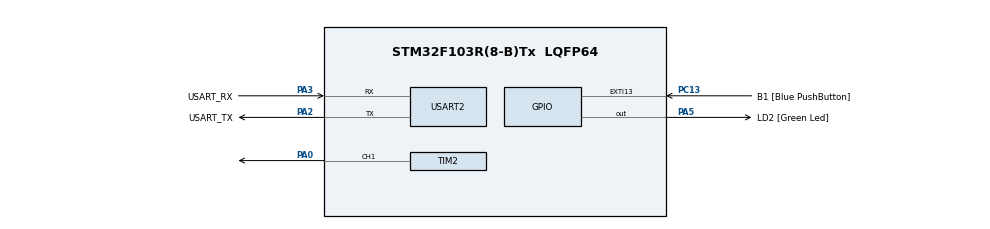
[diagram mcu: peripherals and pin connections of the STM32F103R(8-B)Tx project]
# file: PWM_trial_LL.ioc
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Mcu.Family=STM32F1
Mcu.Name=STM32F103R(8-B)Tx
Mcu.Package=LQFP64
NVIC.EXTI15_10_IRQn=true\:0\:0\:false\:false\:true\:true\:true
NVIC.PriorityGroup=NVIC_PRIORITYGROUP_4
PA0-WKUP.Signal=S_TIM2_CH1_ETR
PA13.GPIO_Label=TMS
PA13.Mode=Serial_Wire
PA13.Signal=SYS_JTMS-SWDIO
PA14.GPIO_Label=TCK
PA14.Mode=Serial_Wire
PA14.Signal=SYS_JTCK-SWCLK
PA2.GPIO_Label=USART_TX
PA2.GPIO_Mode=GPIO_MODE_AF_PP
PA2.GPIO_PuPd=GPIO_NOPULL
PA2.GPIO_Speed=GPIO_SPEED_FREQ_LOW
PA2.Mode=Asynchronous
PA2.Signal=USART2_TX
PA3.GPIO_Label=USART_RX
PA3.GPIO_Mode=GPIO_MODE_AF_PP
PA3.GPIO_PuPd=GPIO_NOPULL
PA3.GPIO_Speed=GPIO_SPEED_FREQ_LOW
PA3.Mode=Asynchronous
PA3.Signal=USART2_RX
PA5.GPIO_Label=LD2 [Green Led]
PA5.GPIO_ModeDefaultOutputPP=GPIO_MODE_OUTPUT_PP
PA5.GPIO_PuPd=GPIO_NOPULL
PA5.GPIO_Speed=GPIO_SPEED_FREQ_LOW
PA5.Signal=GPIO_Output
PB3.GPIO_Label=SWO
PB3.Signal=SYS_JTDO-TRACESWO
PC13-TAMPER-RTC.GPIO_Label=B1 [Blue PushButton]
PC13-TAMPER-RTC.GPIO_PuPd=GPIO_NOPULL
PC13-TAMPER-RTC.Signal=GPXTI13
PC14-OSC32_IN.Mode=LSE-External-Oscillator
PC14-OSC32_IN.Signal=RCC_OSC32_IN
PC15-OSC32_OUT.Mode=LSE-External-Oscillator
PC15-OSC32_OUT.Signal=RCC_OSC32_OUT
PD0-OSC_IN.Mode=HSE-External-Clock-Source
PD0-OSC_IN.Signal=RCC_OSC_IN
PD1-OSC_OUT.Mode=HSE-External-Clock-Source
PD1-OSC_OUT.Signal=RCC_OSC_OUT
ProjectManager.HeapSize=0x200
ProjectManager.StackSize=0x400
ProjectManager.TargetToolchain=SW4STM32
RCC.AHBFreq_Value=64000000
RCC.APB1CLKDivider=RCC_HCLK_DIV2
RCC.APB1Freq_Value=32000000
RCC.APB1TimFreq_Value=64000000
RCC.APB2Freq_Value=64000000
RCC.APB2TimFreq_Value=64000000
RCC.HCLKFreq_Value=64000000
RCC.PLLMUL=RCC_PLL_MUL16
RCC.RTCClockSelection=RCC_RTCCLKSOURCE_LSE
RCC.SYSCLKFreq_VALUE=64000000
RCC.SYSCLKSource=RCC_SYSCLKSOURCE_PLLCLK
RCC.USBFreq_Value=64000000
SH.S_TIM2_CH1_ETR.0=TIM2_CH1,PWM Generation1 CH1
TIM2.Channel-PWM\ Generation1\ CH1=TIM_CHANNEL_1
TIM2.Period=1000
TIM2.Prescaler=20
USART2.VirtualMode=VM_ASYNC
VP_TIM2_VS_ClockSourceINT.Mode=Internal
board=NUCLEO-F103RB

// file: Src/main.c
/* USER CODE BEGIN Header */
/**
  ******************************************************************************
  * @file           : main.c
  * @brief          : Main program body
  ******************************************************************************
  * @attention
  *
  * <h2><center>&copy; Copyright (c) 2020 STMicroelectronics.
  * All rights reserved.</center></h2>
  *
  * This software component is licensed by ST under BSD 3-Clause license,
  * the "License"; You may not use this file except in compliance with the
  * License. You may obtain a copy of the License at:
  *                        opensource.org/licenses/BSD-3-Clause
  *
  ******************************************************************************
  */
/* USER CODE END Header */

#include "main.h"

/* USER CODE BEGIN Includes */

#include "PWM_LL_library.h"

/* USER CODE END Includes */

void SystemClock_Config(void);
static void MX_GPIO_Init(void);
static void MX_TIM2_Init(void);
static void MX_USART2_UART_Init(void);

int main(void)
{

  /* MCU Configuration--------------------------------------------------------*/

  /* Reset of all peripherals, Initializes the Flash interface and the Systick. */

  LL_APB2_GRP1_EnableClock(LL_APB2_GRP1_PERIPH_AFIO);
  LL_APB1_GRP1_EnableClock(LL_APB1_GRP1_PERIPH_PWR);

  NVIC_SetPriorityGrouping(NVIC_PRIORITYGROUP_4);

  /* System interrupt init*/

  /** NOJTAG: JTAG-DP Disabled and SW-DP Enabled
  */
  LL_GPIO_AF_Remap_SWJ_NOJTAG();

  /* Configure the system clock */
  SystemClock_Config();

  /* Initialize all configured peripherals */
  MX_GPIO_Init();
  MX_TIM2_Init();
  MX_USART2_UART_Init();
  /* USER CODE BEGIN 2 */

  TIM_handler_t tim;
  PWM_init(&tim, TIM2, 64000); 					// frequency 64000 Hz
  PWM_setDutyCycle(&tim, 10);					//duty cycle 10%
  PWM_enable(&tim);								//enabling PWM
  for(int i = 0; i < 16000000; i++) __NOP();	// delay
  PWM_disable(&tim);							//disabling PWM
  PWM_setDutyCycle(&tim, 90);					//setting duty cycle to 90%
  PWM_enable(&tim);								//enabling

  /* USER CODE END 2 */

  /* Infinite loop */
  while (1)
  {

  }
}

void SystemClock_Config(void)
{
  LL_FLASH_SetLatency(LL_FLASH_LATENCY_2);

   if(LL_FLASH_GetLatency() != LL_FLASH_LATENCY_2)
  {
    Error_Handler();
  }
  LL_RCC_HSI_SetCalibTrimming(16);
  LL_RCC_HSI_Enable();

   /* Wait till HSI is ready */
  while(LL_RCC_HSI_IsReady() != 1)
  {

  }
  LL_RCC_PLL_ConfigDomain_SYS(LL_RCC_PLLSOURCE_HSI_DIV_2, LL_RCC_PLL_MUL_16);
  LL_RCC_PLL_Enable();

   /* Wait till PLL is ready */
  while(LL_RCC_PLL_IsReady() != 1)
  {

  }
  LL_RCC_SetAHBPrescaler(LL_RCC_SYSCLK_DIV_1);
  LL_RCC_SetAPB1Prescaler(LL_RCC_APB1_DIV_2);
  LL_RCC_SetAPB2Prescaler(LL_RCC_APB2_DIV_1);
  LL_RCC_SetSysClkSource(LL_RCC_SYS_CLKSOURCE_PLL);

   /* Wait till System clock is ready */
  while(LL_RCC_GetSysClkSource() != LL_RCC_SYS_CLKSOURCE_STATUS_PLL)
  {

  }
  LL_Init1msTick(64000000);
  LL_SYSTICK_SetClkSource(LL_SYSTICK_CLKSOURCE_HCLK);
  LL_SetSystemCoreClock(64000000);
}

static void MX_TIM2_Init(void)
{

  LL_TIM_InitTypeDef TIM_InitStruct = {0};
  LL_TIM_OC_InitTypeDef TIM_OC_InitStruct = {0};

  LL_GPIO_InitTypeDef GPIO_InitStruct = {0};

  /* Peripheral clock enable */
  LL_APB1_GRP1_EnableClock(LL_APB1_GRP1_PERIPH_TIM2);

  TIM_InitStruct.Prescaler = 20;
  TIM_InitStruct.CounterMode = LL_TIM_COUNTERMODE_UP;
  TIM_InitStruct.Autoreload = 1000;
  TIM_InitStruct.ClockDivision = LL_TIM_CLOCKDIVISION_DIV1;
  LL_TIM_Init(TIM2, &TIM_InitStruct);
  LL_TIM_DisableARRPreload(TIM2);
  LL_TIM_SetClockSource(TIM2, LL_TIM_CLOCKSOURCE_INTERNAL);
  LL_TIM_OC_EnablePreload(TIM2, LL_TIM_CHANNEL_CH1);
  TIM_OC_InitStruct.OCMode = LL_TIM_OCMODE_PWM1;
  TIM_OC_InitStruct.OCState = LL_TIM_OCSTATE_DISABLE;
  TIM_OC_InitStruct.OCNState = LL_TIM_OCSTATE_DISABLE;
  TIM_OC_InitStruct.CompareValue = 0;
  TIM_OC_InitStruct.OCPolarity = LL_TIM_OCPOLARITY_HIGH;
  LL_TIM_OC_Init(TIM2, LL_TIM_CHANNEL_CH1, &TIM_OC_InitStruct);
  LL_TIM_OC_DisableFast(TIM2, LL_TIM_CHANNEL_CH1);
  LL_TIM_SetTriggerOutput(TIM2, LL_TIM_TRGO_RESET);
  LL_TIM_DisableMasterSlaveMode(TIM2);
  LL_APB2_GRP1_EnableClock(LL_APB2_GRP1_PERIPH_GPIOA);
  /**TIM2 GPIO Configuration
  PA0-WKUP   ------> TIM2_CH1
  */
  GPIO_InitStruct.Pin = LL_GPIO_PIN_0;
  GPIO_InitStruct.Mode = LL_GPIO_MODE_ALTERNATE;
  GPIO_InitStruct.Speed = LL_GPIO_SPEED_FREQ_LOW;
  GPIO_InitStruct.OutputType = LL_GPIO_OUTPUT_PUSHPULL;
  LL_GPIO_Init(GPIOA, &GPIO_InitStruct);

}

static void MX_USART2_UART_Init(void)
{

  LL_USART_InitTypeDef USART_InitStruct = {0};

  LL_GPIO_InitTypeDef GPIO_InitStruct = {0};

  /* Peripheral clock enable */
  LL_APB1_GRP1_EnableClock(LL_APB1_GRP1_PERIPH_USART2);

  LL_APB2_GRP1_EnableClock(LL_APB2_GRP1_PERIPH_GPIOA);
  /**USART2 GPIO Configuration
  PA2   ------> USART2_TX
  PA3   ------> USART2_RX
  */
  GPIO_InitStruct.Pin = USART_TX_Pin;
  GPIO_InitStruct.Mode = LL_GPIO_MODE_ALTERNATE;
  GPIO_InitStruct.Speed = LL_GPIO_SPEED_FREQ_LOW;
  GPIO_InitStruct.OutputType = LL_GPIO_OUTPUT_PUSHPULL;
  LL_GPIO_Init(USART_TX_GPIO_Port, &GPIO_InitStruct);

  GPIO_InitStruct.Pin = USART_RX_Pin;
  GPIO_InitStruct.Mode = LL_GPIO_MODE_ALTERNATE;
  LL_GPIO_Init(USART_RX_GPIO_Port, &GPIO_InitStruct);

  USART_InitStruct.BaudRate = 115200;
  USART_InitStruct.DataWidth = LL_USART_DATAWIDTH_8B;
  USART_InitStruct.StopBits = LL_USART_STOPBITS_1;
  USART_InitStruct.Parity = LL_USART_PARITY_NONE;
  USART_InitStruct.TransferDirection = LL_USART_DIRECTION_TX_RX;
  USART_InitStruct.HardwareFlowControl = LL_USART_HWCONTROL_NONE;
  USART_InitStruct.OverSampling = LL_USART_OVERSAMPLING_16;
  LL_USART_Init(USART2, &USART_InitStruct);
  LL_USART_ConfigAsyncMode(USART2);
  LL_USART_Enable(USART2);

}

static void MX_GPIO_Init(void)
{
  LL_EXTI_InitTypeDef EXTI_InitStruct = {0};
  LL_GPIO_InitTypeDef GPIO_InitStruct = {0};

  /* GPIO Ports Clock Enable */
  LL_APB2_GRP1_EnableClock(LL_APB2_GRP1_PERIPH_GPIOC);
  LL_APB2_GRP1_EnableClock(LL_APB2_GRP1_PERIPH_GPIOD);
  LL_APB2_GRP1_EnableClock(LL_APB2_GRP1_PERIPH_GPIOA);
  LL_APB2_GRP1_EnableClock(LL_APB2_GRP1_PERIPH_GPIOB);

  /**/
  LL_GPIO_ResetOutputPin(LD2_GPIO_Port, LD2_Pin);

  /**/
  LL_GPIO_AF_SetEXTISource(LL_GPIO_AF_EXTI_PORTC, LL_GPIO_AF_EXTI_LINE13);

  /**/
  EXTI_InitStruct.Line_0_31 = LL_EXTI_LINE_13;
  EXTI_InitStruct.LineCommand = ENABLE;
  EXTI_InitStruct.Mode = LL_EXTI_MODE_IT;
  EXTI_InitStruct.Trigger = LL_EXTI_TRIGGER_RISING;
  LL_EXTI_Init(&EXTI_InitStruct);

  /**/
  LL_GPIO_SetPinMode(B1_GPIO_Port, B1_Pin, LL_GPIO_MODE_FLOATING);

  /**/
  GPIO_InitStruct.Pin = LD2_Pin;
  GPIO_InitStruct.Mode = LL_GPIO_MODE_OUTPUT;
  GPIO_InitStruct.Speed = LL_GPIO_SPEED_FREQ_LOW;
  GPIO_InitStruct.OutputType = LL_GPIO_OUTPUT_PUSHPULL;
  LL_GPIO_Init(LD2_GPIO_Port, &GPIO_InitStruct);

  /* EXTI interrupt init*/
  NVIC_SetPriority(EXTI15_10_IRQn, NVIC_EncodePriority(NVIC_GetPriorityGrouping(),0, 0));
  NVIC_EnableIRQ(EXTI15_10_IRQn);

}

void Error_Handler(void)
{
}

/************************ (C) COPYRIGHT STMicroelectronics *****END OF FILE****/
